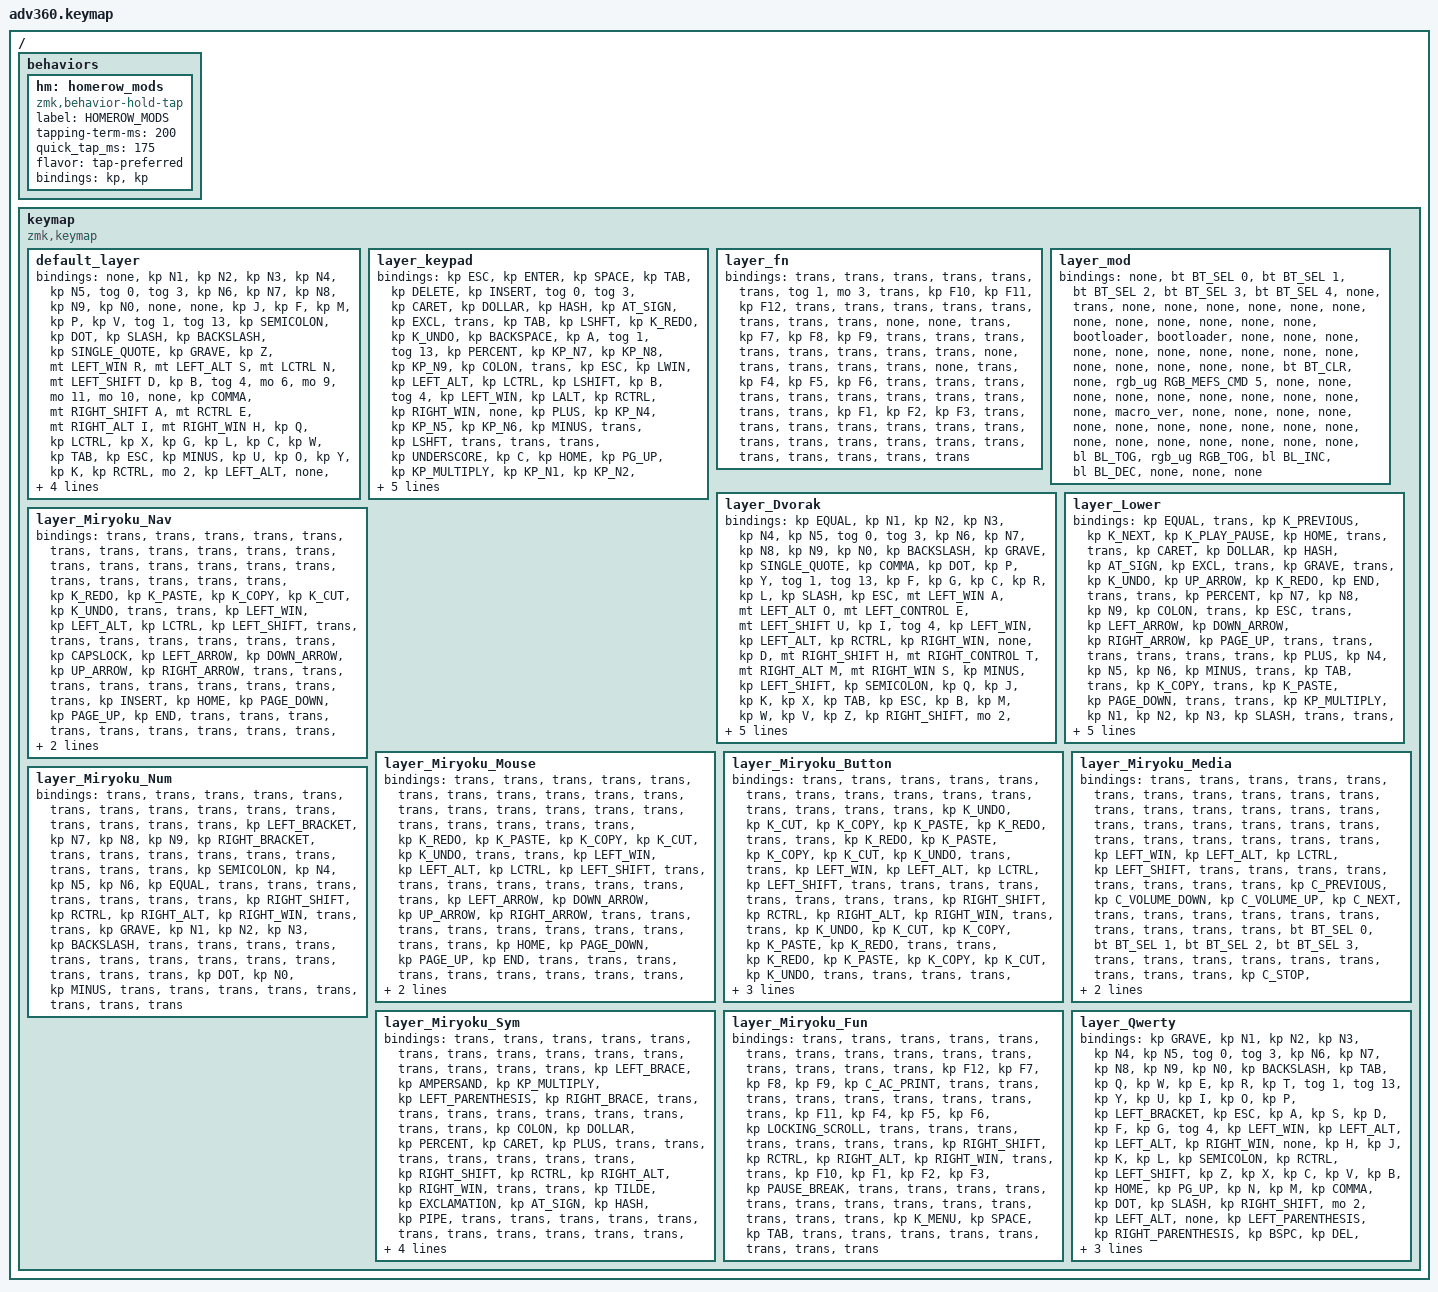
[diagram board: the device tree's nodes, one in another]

/*
 * Copyright (c) 2020 The ZMK Contributors
 *
 * SPDX-License-Identifier: MIT
 */


/* THIS FILE WAS GENERATED!
 *
 * This file was generated automatically. You may or may not want to
 * edit it directly.
 */

#include <behaviors.dtsi>
#include <dt-bindings/zmk/keys.h>
#include <dt-bindings/zmk/bt.h>
#include <dt-bindings/zmk/rgb.h>
#include <dt-bindings/zmk/backlight.h>

/ {
  behaviors {
    #include "macros.dtsi"
    #include "version.dtsi"

    hm: homerow_mods {
        compatible = "zmk,behavior-hold-tap";
        label = "HOMEROW_MODS";
        #binding-cells = <2>;
        tapping-term-ms = <200>;
        quick_tap_ms = <175>;
        flavor = "tap-preferred";
        bindings = <&kp>, <&kp>;
    };
  };

    keymap {
        compatible = "zmk,keymap";


        default_layer {
            bindings = <
     &none          &kp N1          &kp N2                &kp N3                 &kp N4  &kp N5                &tog 0                                                                         &tog 3         &kp N6             &kp N7             &kp N8           &kp N9            &kp N0      &none
     &none           &kp J           &kp F                 &kp M                  &kp P   &kp V                &tog 1                                                                        &tog 13  &kp SEMICOLON            &kp DOT          &kp SLASH    &kp BACKSLASH  &kp SINGLE_QUOTE  &kp GRAVE
     &kp Z  &mt LEFT_WIN R  &mt LEFT_ALT S           &mt LCTRL N       &mt LEFT_SHIFT D   &kp B                &tog 4    &mo 6      &mo 9                         &mo 11        &mo 10         &none      &kp COMMA  &mt RIGHT_SHIFT A        &mt RCTRL E  &mt RIGHT_ALT I   &mt RIGHT_WIN H      &kp Q
 &kp LCTRL           &kp X           &kp G                 &kp L                  &kp C   &kp W                                   &kp TAB                        &kp ESC                                  &kp MINUS              &kp U              &kp O            &kp Y             &kp K  &kp RCTRL
     &mo 2    &kp LEFT_ALT           &none  &kp LEFT_PARENTHESIS  &kp RIGHT_PARENTHESIS                    &lt 9 BSPC  &lt 6 T  &lt 7 DEL                  &lt 11 DELETE  &lt 10 ENTER  &lt 12 SPACE                  &kp LEFT_BRACKET  &kp RIGHT_BRACKET            &none     &kp RIGHT_ALT      &mo 2
            >;
        };

        layer_keypad {
            bindings = <
   &kp ESC  &kp ENTER     &kp SPACE     &kp TAB      &kp DELETE  &kp INSERT              &tog 0                                                                       &tog 3        &kp CARET            &kp DOLLAR          &kp HASH        &kp AT_SIGN               &kp EXCL     &trans
   &kp TAB  &kp LSHFT    &kp K_REDO  &kp K_UNDO   &kp BACKSPACE       &kp A              &tog 1                                                                      &tog 13      &kp PERCENT             &kp KP_N7         &kp KP_N8          &kp KP_N9              &kp COLON     &trans
   &kp ESC   &kp LWIN  &kp LEFT_ALT   &kp LCTRL      &kp LSHIFT       &kp B              &tog 4  &kp LEFT_WIN  &kp LALT                  &kp RCTRL  &kp RIGHT_WIN      &none         &kp PLUS             &kp KP_N4         &kp KP_N5          &kp KP_N6              &kp MINUS     &trans
 &kp LSHFT     &trans        &trans      &trans  &kp UNDERSCORE       &kp C                                    &kp HOME                  &kp PG_UP                            &kp KP_MULTIPLY             &kp KP_N1         &kp KP_N2          &kp KP_N3              &kp SLASH  &kp RSHFT
     &mo 2     &trans        &trans    &kp LEFT       &kp RIGHT                        &kp BSPC       &kp DEL   &kp END                  &kp PG_DN      &kp ENTER  &kp KP_N0                   &kp LEFT_PARENTHESIS  &kp LEFT_BRACKET  &kp RIGHT_BRACKET  &kp RIGHT_PARENTHESIS      &mo 2
            >;
        };

        layer_fn {
            bindings = <
 &trans  &trans  &trans  &trans  &trans  &trans            &tog 1                                                   &mo 3  &trans  &kp F10  &kp F11  &kp F12  &trans  &trans
 &trans  &trans  &trans  &trans  &trans  &trans             &none                                                   &none  &trans   &kp F7   &kp F8   &kp F9  &trans  &trans
 &trans  &trans  &trans  &trans  &trans  &trans             &none  &trans  &trans                  &trans  &trans   &none  &trans   &kp F4   &kp F5   &kp F6  &trans  &trans
 &trans  &trans  &trans  &trans  &trans  &trans                            &trans                  &trans                  &trans   &kp F1   &kp F2   &kp F3  &trans  &trans
 &trans  &trans  &trans  &trans  &trans                    &trans  &trans  &trans                  &trans  &trans  &trans           &trans   &trans   &trans  &trans  &trans
            >;
        };

        layer_mod {
            bindings = <
  &none  &bt BT_SEL 0  &bt BT_SEL 1  &bt BT_SEL 2  &bt BT_SEL 3  &bt BT_SEL 4                  &none                                                                          &trans   &none       &none       &none   &none   &none   &none
  &none         &none         &none         &none         &none         &none            &bootloader                                                                     &bootloader   &none       &none       &none   &none   &none   &none
  &none         &none         &none         &none         &none         &none                  &none   &none   &none                  &bt BT_CLR       &none  &rgb_ug RGB_MEFS_CMD 5   &none       &none       &none   &none   &none   &none
  &none         &none         &none         &none    &macro_ver         &none                                  &none                       &none                                       &none       &none       &none   &none   &none   &none
  &none         &none         &none         &none         &none                                &none   &none   &none                       &none  &bl BL_TOG         &rgb_ug RGB_TOG          &bl BL_INC  &bl BL_DEC   &none   &none   &none
            >;
        };

        layer_Dvorak {
            bindings = <
      &kp EQUAL            &kp N1          &kp N2              &kp N3            &kp N4  &kp N5              &tog 0                                                                           &tog 3  &kp N6                &kp N7               &kp N8             &kp N9                 &kp N0    &kp BACKSLASH
      &kp GRAVE  &kp SINGLE_QUOTE       &kp COMMA             &kp DOT             &kp P   &kp Y              &tog 1                                                                          &tog 13   &kp F                 &kp G                &kp C              &kp R                  &kp L        &kp SLASH
        &kp ESC    &mt LEFT_WIN A  &mt LEFT_ALT O  &mt LEFT_CONTROL E  &mt LEFT_SHIFT U   &kp I              &tog 4  &kp LEFT_WIN  &kp LEFT_ALT                  &kp RCTRL  &kp RIGHT_WIN      &none   &kp D     &mt RIGHT_SHIFT H  &mt RIGHT_CONTROL T    &mt RIGHT_ALT M        &mt RIGHT_WIN S        &kp MINUS
 &kp LEFT_SHIFT     &kp SEMICOLON           &kp Q               &kp J             &kp K   &kp X                                         &kp TAB                    &kp ESC                             &kp B                 &kp M                &kp W              &kp V                  &kp Z  &kp RIGHT_SHIFT
          &mo 2          &kp HOME       &kp PG_UP           &kp PG_DN           &kp END                    &kp BSPC       &kp DEL         &mo 5                      &mo 5      &kp ENTER  &kp SPACE          &kp LEFT_PARENTHESIS     &kp LEFT_BRACKET  &kp RIGHT_BRACKET  &kp RIGHT_PARENTHESIS            &mo 2
            >;
        };

        layer_Lower {
            bindings = <
 &kp EQUAL      &trans  &kp K_PREVIOUS      &kp K_NEXT  &kp K_PLAY_PAUSE       &kp HOME            &trans                                                  &trans        &kp CARET            &kp DOLLAR          &kp HASH        &kp AT_SIGN               &kp EXCL  &trans
 &kp GRAVE      &trans      &kp K_UNDO    &kp UP_ARROW        &kp K_REDO        &kp END            &trans                                                  &trans      &kp PERCENT                &kp N7            &kp N8             &kp N9              &kp COLON  &trans
   &kp ESC      &trans  &kp LEFT_ARROW  &kp DOWN_ARROW   &kp RIGHT_ARROW    &kp PAGE_UP            &trans  &trans  &trans                  &trans  &trans  &trans         &kp PLUS                &kp N4            &kp N5             &kp N6              &kp MINUS  &trans
   &kp TAB      &trans      &kp K_COPY          &trans       &kp K_PASTE  &kp PAGE_DOWN                            &trans                  &trans                  &kp KP_MULTIPLY                &kp N1            &kp N2             &kp N3              &kp SLASH  &trans
    &trans  &kp K_MENU    &kp K_VOL_DN    &kp K_VOL_UP        &kp K_MUTE                           &trans  &trans  &trans                  &trans  &trans  &kp N0                   &kp LEFT_PARENTHESIS  &kp LEFT_BRACKET  &kp RIGHT_BRACKET  &kp RIGHT_PARENTHESIS  &trans
            >;
        };

        layer_Miryoku_Nav {
            bindings = <
 &trans        &trans        &trans     &trans          &trans  &trans            &trans                                                             &trans        &trans          &trans          &trans        &trans           &trans  &trans
 &trans        &trans        &trans     &trans          &trans  &trans            &trans                                                             &trans    &kp K_REDO     &kp K_PASTE      &kp K_COPY     &kp K_CUT       &kp K_UNDO  &trans
 &trans  &kp LEFT_WIN  &kp LEFT_ALT  &kp LCTRL  &kp LEFT_SHIFT  &trans            &trans  &trans  &trans                     &trans         &trans   &trans  &kp CAPSLOCK  &kp LEFT_ARROW  &kp DOWN_ARROW  &kp UP_ARROW  &kp RIGHT_ARROW  &trans
 &trans        &trans        &trans     &trans          &trans  &trans                            &trans                     &trans                            &kp INSERT        &kp HOME   &kp PAGE_DOWN   &kp PAGE_UP          &kp END  &trans
 &trans        &trans        &trans     &trans          &trans                    &trans  &trans  &trans                  &kp ENTER  &kp BACKSPACE  &kp DEL                        &trans          &trans        &trans           &trans  &trans
            >;
        };

        layer_Miryoku_Mouse {
            bindings = <
 &trans        &trans        &trans     &trans          &trans  &trans            &trans                                                  &trans      &trans          &trans          &trans        &trans           &trans  &trans
 &trans        &trans        &trans     &trans          &trans  &trans            &trans                                                  &trans  &kp K_REDO     &kp K_PASTE      &kp K_COPY     &kp K_CUT       &kp K_UNDO  &trans
 &trans  &kp LEFT_WIN  &kp LEFT_ALT  &kp LCTRL  &kp LEFT_SHIFT  &trans            &trans  &trans  &trans                  &trans  &trans  &trans      &trans  &kp LEFT_ARROW  &kp DOWN_ARROW  &kp UP_ARROW  &kp RIGHT_ARROW  &trans
 &trans        &trans        &trans     &trans          &trans  &trans                            &trans                  &trans                      &trans        &kp HOME   &kp PAGE_DOWN   &kp PAGE_UP          &kp END  &trans
 &trans        &trans        &trans     &trans          &trans                    &trans  &trans  &trans                  &trans  &trans  &trans                      &trans          &trans        &trans           &trans  &trans
            >;
        };

        layer_Miryoku_Button {
            bindings = <
 &trans        &trans        &trans      &trans          &trans      &trans            &trans                                                  &trans      &trans           &trans      &trans         &trans         &trans  &trans
 &trans    &kp K_UNDO     &kp K_CUT  &kp K_COPY     &kp K_PASTE  &kp K_REDO            &trans                                                  &trans  &kp K_REDO      &kp K_PASTE  &kp K_COPY      &kp K_CUT     &kp K_UNDO  &trans
 &trans  &kp LEFT_WIN  &kp LEFT_ALT   &kp LCTRL  &kp LEFT_SHIFT      &trans            &trans  &trans  &trans                  &trans  &trans  &trans      &trans  &kp RIGHT_SHIFT   &kp RCTRL  &kp RIGHT_ALT  &kp RIGHT_WIN  &trans
 &trans    &kp K_UNDO     &kp K_CUT  &kp K_COPY     &kp K_PASTE  &kp K_REDO                            &trans                  &trans                  &kp K_REDO      &kp K_PASTE  &kp K_COPY      &kp K_CUT     &kp K_UNDO  &trans
 &trans        &trans        &trans      &trans          &trans                        &trans  &trans  &trans                  &trans  &trans  &trans                       &trans      &trans         &trans         &trans  &trans
            >;
        };

        layer_Miryoku_Media {
            bindings = <
 &trans        &trans        &trans     &trans          &trans  &trans            &trans                                                                    &trans  &trans          &trans             &trans           &trans        &trans  &trans
 &trans        &trans        &trans     &trans          &trans  &trans            &trans                                                                    &trans  &trans          &trans             &trans           &trans        &trans  &trans
 &trans  &kp LEFT_WIN  &kp LEFT_ALT  &kp LCTRL  &kp LEFT_SHIFT  &trans            &trans  &trans  &trans                      &trans            &trans      &trans  &trans  &kp C_PREVIOUS  &kp C_VOLUME_DOWN  &kp C_VOLUME_UP    &kp C_NEXT  &trans
 &trans        &trans        &trans     &trans          &trans  &trans                            &trans                      &trans                                &trans    &bt BT_SEL 0       &bt BT_SEL 1     &bt BT_SEL 2  &bt BT_SEL 3  &trans
 &trans        &trans        &trans     &trans          &trans                    &trans  &trans  &trans                  &kp C_STOP  &kp C_PLAY_PAUSE  &kp C_MUTE                  &trans             &trans           &trans        &trans  &trans
            >;
        };

        layer_Miryoku_Num {
            bindings = <
 &trans            &trans  &trans  &trans  &trans             &trans             &trans                                                     &trans  &trans           &trans     &trans         &trans         &trans  &trans
 &trans  &kp LEFT_BRACKET  &kp N7  &kp N8  &kp N9  &kp RIGHT_BRACKET             &trans                                                     &trans  &trans           &trans     &trans         &trans         &trans  &trans
 &trans     &kp SEMICOLON  &kp N4  &kp N5  &kp N6          &kp EQUAL             &trans  &trans     &trans                  &trans  &trans  &trans  &trans  &kp RIGHT_SHIFT  &kp RCTRL  &kp RIGHT_ALT  &kp RIGHT_WIN  &trans
 &trans         &kp GRAVE  &kp N1  &kp N2  &kp N3      &kp BACKSLASH                                &trans                  &trans                  &trans           &trans     &trans         &trans         &trans  &trans
 &trans            &trans  &trans  &trans  &trans                               &kp DOT  &kp N0  &kp MINUS                  &trans  &trans  &trans                   &trans     &trans         &trans         &trans  &trans
            >;
        };

        layer_Miryoku_Sym {
            bindings = <
 &trans          &trans           &trans           &trans                &trans           &trans                          &trans                                                                    &trans  &trans           &trans     &trans         &trans         &trans  &trans
 &trans  &kp LEFT_BRACE    &kp AMPERSAND  &kp KP_MULTIPLY  &kp LEFT_PARENTHESIS  &kp RIGHT_BRACE                          &trans                                                                    &trans  &trans           &trans     &trans         &trans         &trans  &trans
 &trans       &kp COLON       &kp DOLLAR      &kp PERCENT             &kp CARET         &kp PLUS                          &trans                 &trans     &trans                  &trans  &trans  &trans  &trans  &kp RIGHT_SHIFT  &kp RCTRL  &kp RIGHT_ALT  &kp RIGHT_WIN  &trans
 &trans       &kp TILDE  &kp EXCLAMATION      &kp AT_SIGN              &kp HASH         &kp PIPE                                                            &trans                  &trans                  &trans           &trans     &trans         &trans         &trans  &trans
 &trans          &trans           &trans           &trans                &trans                             &kp LEFT_PARENTHESIS  &kp RIGHT_PARENTHESIS  &kp MINUS                  &trans  &trans  &trans                   &trans     &trans         &trans         &trans  &trans
            >;
        };

        layer_Miryoku_Fun {
            bindings = <
 &trans   &trans  &trans  &trans  &trans              &trans                &trans                                                      &trans  &trans           &trans     &trans         &trans         &trans  &trans
 &trans  &kp F12  &kp F7  &kp F8  &kp F9      &kp C_AC_PRINT                &trans                                                      &trans  &trans           &trans     &trans         &trans         &trans  &trans
 &trans  &kp F11  &kp F4  &kp F5  &kp F6  &kp LOCKING_SCROLL                &trans     &trans   &trans                  &trans  &trans  &trans  &trans  &kp RIGHT_SHIFT  &kp RCTRL  &kp RIGHT_ALT  &kp RIGHT_WIN  &trans
 &trans  &kp F10  &kp F1  &kp F2  &kp F3     &kp PAUSE_BREAK                                    &trans                  &trans                  &trans           &trans     &trans         &trans         &trans  &trans
 &trans   &trans  &trans  &trans  &trans                                &kp K_MENU  &kp SPACE  &kp TAB                  &trans  &trans  &trans                   &trans     &trans         &trans         &trans  &trans
            >;
        };

        layer_Qwerty {
            bindings = <
      &kp GRAVE        &kp N1  &kp N2                &kp N3                 &kp N4  &kp N5              &tog 0                                                                              &tog 3  &kp N6          &kp N7           &kp N8        &kp N9          &kp N0     &kp BACKSLASH
        &kp TAB         &kp Q   &kp W                 &kp E                  &kp R   &kp T              &tog 1                                                                             &tog 13   &kp Y           &kp U            &kp I         &kp O           &kp P  &kp LEFT_BRACKET
        &kp ESC         &kp A   &kp S                 &kp D                  &kp F   &kp G              &tog 4  &kp LEFT_WIN  &kp LEFT_ALT                  &kp LEFT_ALT  &kp RIGHT_WIN      &none   &kp H           &kp J            &kp K         &kp L   &kp SEMICOLON         &kp RCTRL
 &kp LEFT_SHIFT         &kp Z   &kp X                 &kp C                  &kp V   &kp B                                        &kp HOME                     &kp PG_UP                             &kp N           &kp M        &kp COMMA       &kp DOT       &kp SLASH   &kp RIGHT_SHIFT
          &mo 2  &kp LEFT_ALT   &none  &kp LEFT_PARENTHESIS  &kp RIGHT_PARENTHESIS                    &kp BSPC       &kp DEL       &kp END                     &kp PG_DN      &kp ENTER  &kp SPACE          &kp LEFT_ARROW  &kp RIGHT_ARROW  &kp UP_ARROW  &kp DOWN_ARROW             &mo 2
            >;
        };

    };
};
